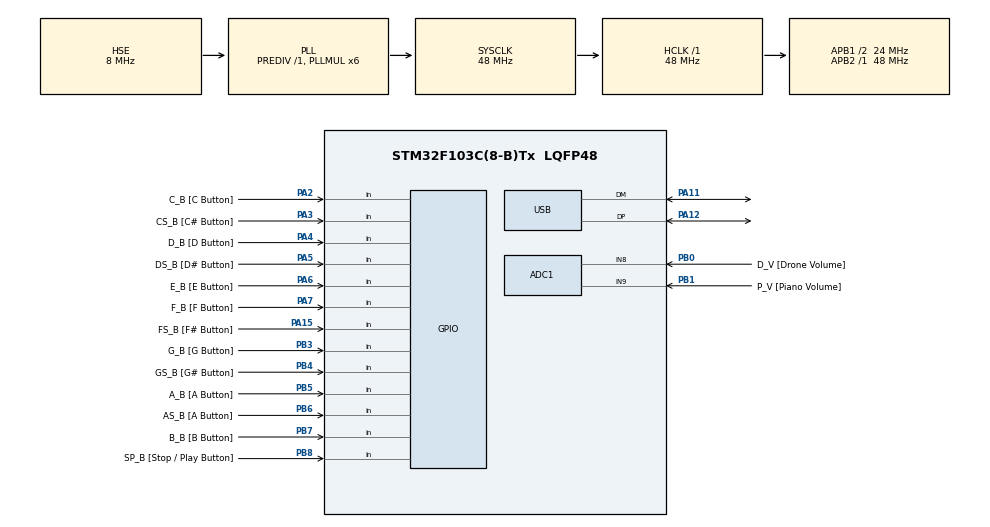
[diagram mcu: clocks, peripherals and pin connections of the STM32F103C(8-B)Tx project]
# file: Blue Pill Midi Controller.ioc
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ADC1.Channel-2\#ChannelRegularConversion=ADC_CHANNEL_8
ADC1.Channel-3\#ChannelRegularConversion=ADC_CHANNEL_9
ADC1.NbrOfConversion=2
ADC1.NbrOfConversionFlag=1
ADC1.Rank-2\#ChannelRegularConversion=1
ADC1.Rank-3\#ChannelRegularConversion=2
ADC1.SamplingTime-2\#ChannelRegularConversion=ADC_SAMPLETIME_1CYCLE_5
ADC1.SamplingTime-3\#ChannelRegularConversion=ADC_SAMPLETIME_1CYCLE_5
ADC1.master=1
Mcu.Family=STM32F1
Mcu.Name=STM32F103C(8-B)Tx
Mcu.Package=LQFP48
NVIC.PriorityGroup=NVIC_PRIORITYGROUP_4
NVIC.TIM2_IRQn=true\:0\:0\:false\:false\:true\:true\:true\:true
NVIC.USB_LP_CAN1_RX0_IRQn=true\:0\:0\:false\:false\:true\:false\:true\:true
PA11.Mode=Device
PA11.Signal=USB_DM
PA12.Mode=Device
PA12.Signal=USB_DP
PA13.Mode=Serial_Wire
PA13.Signal=SYS_JTMS-SWDIO
PA14.Mode=Serial_Wire
PA14.Signal=SYS_JTCK-SWCLK
PA15.GPIO_Label=FS_B [F\# Button]
PA15.GPIO_PuPd=GPIO_PULLUP
PA15.Signal=GPIO_Input
PA2.GPIO_Label=C_B [C Button]
PA2.GPIO_PuPd=GPIO_PULLUP
PA2.Signal=GPIO_Input
PA3.GPIO_Label=CS_B [C\# Button]
PA3.GPIO_PuPd=GPIO_PULLUP
PA3.Signal=GPIO_Input
PA4.GPIO_Label=D_B [D Button]
PA4.GPIO_PuPd=GPIO_PULLUP
PA4.Signal=GPIO_Input
PA5.GPIO_Label=DS_B [D\# Button]
PA5.GPIO_PuPd=GPIO_PULLUP
PA5.Signal=GPIO_Input
PA6.GPIO_Label=E_B [E Button]
PA6.GPIO_PuPd=GPIO_PULLUP
PA6.Signal=GPIO_Input
PA7.GPIO_Label=F_B [F Button]
PA7.GPIO_PuPd=GPIO_PULLUP
PA7.Signal=GPIO_Input
PB0.GPIO_Label=D_V [Drone Volume]
PB0.Signal=ADCx_IN8
PB1.GPIO_Label=P_V [Piano Volume]
PB1.Signal=ADCx_IN9
PB3.GPIO_Label=G_B [G Button]
PB3.GPIO_PuPd=GPIO_PULLUP
PB3.Signal=GPIO_Input
PB4.GPIO_Label=GS_B [G\# Button]
PB4.GPIO_PuPd=GPIO_PULLUP
PB4.Signal=GPIO_Input
PB5.GPIO_Label=A_B [A Button]
PB5.GPIO_PuPd=GPIO_PULLUP
PB5.Signal=GPIO_Input
PB6.GPIO_Label=AS_B [A Button]
PB6.GPIO_PuPd=GPIO_PULLUP
PB6.Signal=GPIO_Input
PB7.GPIO_Label=B_B [B Button]
PB7.GPIO_PuPd=GPIO_PULLUP
PB7.Signal=GPIO_Input
PB8.GPIO_Label=SP_B [Stop / Play Button]
PB8.GPIO_PuPd=GPIO_PULLUP
PB8.Signal=GPIO_Input
PD0-OSC_IN.Mode=HSE-External-Oscillator
PD0-OSC_IN.Signal=RCC_OSC_IN
PD1-OSC_OUT.Mode=HSE-External-Oscillator
PD1-OSC_OUT.Signal=RCC_OSC_OUT
ProjectManager.HeapSize=0x200
ProjectManager.StackSize=0x400
ProjectManager.TargetToolchain=STM32CubeIDE
RCC.ADCPresc=RCC_ADCPCLK2_DIV4
RCC.AHBFreq_Value=48000000
RCC.APB1CLKDivider=RCC_HCLK_DIV2
RCC.APB1Freq_Value=24000000
RCC.APB1TimFreq_Value=48000000
RCC.APB2Freq_Value=48000000
RCC.APB2TimFreq_Value=48000000
RCC.HCLKFreq_Value=48000000
RCC.PLLMUL=RCC_PLL_MUL6
RCC.SYSCLKFreq_VALUE=48000000
RCC.SYSCLKSource=RCC_SYSCLKSOURCE_PLLCLK
RCC.USBFreq_Value=48000000
SH.ADCx_IN8.0=ADC1_IN8,IN8
SH.ADCx_IN9.0=ADC1_IN9,IN9
TIM2.Period=799
TIM2.Prescaler=359
USB_DEVICE.CLASS_NAME_FS=HID
USB_DEVICE.MANUFACTURER_STRING=Vandar Systems
USB_DEVICE.PRODUCT_STRING_HID_FS=Vandar Midi Controller
USB_DEVICE.VirtualMode=Hid
USB_DEVICE.VirtualModeFS=Hid_FS
VP_TIM2_VS_ClockSourceINT.Mode=Internal
VP_USB_DEVICE_VS_USB_DEVICE_HID_FS.Mode=HID_FS
board=custom

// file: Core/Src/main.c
/* USER CODE BEGIN Header */
/**
  ******************************************************************************
  * @file           : main.c
  * @brief          : Main program body
  ******************************************************************************
  * @attention
  *
  * Copyright (c) 2025 STMicroelectronics.
  * All rights reserved.
  *
  * This software is licensed under terms that can be found in the LICENSE file
  * in the root directory of this software component.
  * If no LICENSE file comes with this software, it is provided AS-IS.
  *
  ******************************************************************************
  */
/* USER CODE END Header */
#include "main.h"
#include "usb_device.h"

/* USER CODE BEGIN Includes */
#include "usbd_midi.h"
/* USER CODE END Includes */

ADC_HandleTypeDef hadc1;

TIM_HandleTypeDef htim2;

/* USER CODE BEGIN PV */
extern USBD_HandleTypeDef hUsbDeviceFS;

extern uint16_t D_previous;
extern uint16_t D_current;
extern uint16_t D_ADC_val[2];

extern uint16_t P_previous;
extern uint16_t P_current;
extern uint16_t P_ADC_val[2];

extern float alpha;

extern uint8_t D_vol_message [4];
extern uint8_t P_vol_message [4];
/* USER CODE END PV */

void SystemClock_Config(void);
static void MX_GPIO_Init(void);
static void MX_ADC1_Init(void);
static void MX_TIM2_Init(void);

int main(void)
{

  /* MCU Configuration--------------------------------------------------------*/

  /* Reset of all peripherals, Initializes the Flash interface and the Systick. */
  HAL_Init();

  /* Configure the system clock */
  SystemClock_Config();

  /* Initialize all configured peripherals */
  MX_GPIO_Init();
  MX_USB_DEVICE_Init();
  MX_ADC1_Init();
  MX_TIM2_Init();
  /* USER CODE BEGIN 2 */
//  HAL_ADC_Start (&hadc1);
//  HAL_ADC_PollForConversion (&hadc1, 100);
//  D_ADC_val[0] = HAL_ADC_GetValue (&hadc1);
//
//  HAL_ADC_Start (&hadc1);
//  HAL_ADC_PollForConversion (&hadc1, 100);
//  P_ADC_val[0] = HAL_ADC_GetValue (&hadc1);
//
//  HAL_ADC_Start (&hadc1);
//  HAL_ADC_PollForConversion (&hadc1, 100);
//  D_ADC_val[1] = HAL_ADC_GetValue (&hadc1);
//
//  HAL_ADC_Start (&hadc1);
//  HAL_ADC_PollForConversion (&hadc1, 100);
//  P_ADC_val[1] = HAL_ADC_GetValue (&hadc1);
//
//  D_current = (alpha * D_ADC_val[1]) + ((1 - alpha) * D_ADC_val[0]);
//  D_current = (D_current * 127) / 4095;
//  D_previous = D_current;
//
//  P_current = (alpha * P_ADC_val[1]) + ((1 - alpha) * P_ADC_val[0]);
//  P_current = (P_current * 127) / 4095;
//  P_previous = P_current;
//
//  D_vol_message [3] = D_current;
//  P_vol_message [3] = P_current;
//
//  while (USBD_MIDI_GetState (&hUsbDeviceFS) != MIDI_IDLE) {}
//  USBD_MIDI_SendPackets (&hUsbDeviceFS, D_vol_message, 4);
//
//  while (USBD_MIDI_GetState (&hUsbDeviceFS) != MIDI_IDLE) {}
//  USBD_MIDI_SendPackets (&hUsbDeviceFS, P_vol_message, 4);

  HAL_NVIC_SetPriority (TIM2_IRQn, 0, 0);
  HAL_NVIC_EnableIRQ (TIM2_IRQn);
  HAL_TIM_Base_Start_IT (&htim2);
  /* USER CODE END 2 */

  /* Infinite loop */
  while (1)
  {

  }
}

void SystemClock_Config(void)
{
  RCC_OscInitTypeDef RCC_OscInitStruct = {0};
  RCC_ClkInitTypeDef RCC_ClkInitStruct = {0};
  RCC_PeriphCLKInitTypeDef PeriphClkInit = {0};

  /** Initializes the RCC Oscillators according to the specified parameters
  * in the RCC_OscInitTypeDef structure.
  */
  RCC_OscInitStruct.OscillatorType = RCC_OSCILLATORTYPE_HSE;
  RCC_OscInitStruct.HSEState = RCC_HSE_ON;
  RCC_OscInitStruct.HSEPredivValue = RCC_HSE_PREDIV_DIV1;
  RCC_OscInitStruct.HSIState = RCC_HSI_ON;
  RCC_OscInitStruct.PLL.PLLState = RCC_PLL_ON;
  RCC_OscInitStruct.PLL.PLLSource = RCC_PLLSOURCE_HSE;
  RCC_OscInitStruct.PLL.PLLMUL = RCC_PLL_MUL6;
  if (HAL_RCC_OscConfig(&RCC_OscInitStruct) != HAL_OK)
  {
    Error_Handler();
  }

  /** Initializes the CPU, AHB and APB buses clocks
  */
  RCC_ClkInitStruct.ClockType = RCC_CLOCKTYPE_HCLK|RCC_CLOCKTYPE_SYSCLK
                              |RCC_CLOCKTYPE_PCLK1|RCC_CLOCKTYPE_PCLK2;
  RCC_ClkInitStruct.SYSCLKSource = RCC_SYSCLKSOURCE_PLLCLK;
  RCC_ClkInitStruct.AHBCLKDivider = RCC_SYSCLK_DIV1;
  RCC_ClkInitStruct.APB1CLKDivider = RCC_HCLK_DIV2;
  RCC_ClkInitStruct.APB2CLKDivider = RCC_HCLK_DIV1;

  if (HAL_RCC_ClockConfig(&RCC_ClkInitStruct, FLASH_LATENCY_1) != HAL_OK)
  {
    Error_Handler();
  }
  PeriphClkInit.PeriphClockSelection = RCC_PERIPHCLK_ADC|RCC_PERIPHCLK_USB;
  PeriphClkInit.AdcClockSelection = RCC_ADCPCLK2_DIV4;
  PeriphClkInit.UsbClockSelection = RCC_USBCLKSOURCE_PLL;
  if (HAL_RCCEx_PeriphCLKConfig(&PeriphClkInit) != HAL_OK)
  {
    Error_Handler();
  }
}

static void MX_ADC1_Init(void)
{

  ADC_ChannelConfTypeDef sConfig = {0};

  /** Common config
  */
  hadc1.Instance = ADC1;
  hadc1.Init.ScanConvMode = ADC_SCAN_ENABLE;
  hadc1.Init.ContinuousConvMode = DISABLE;
  hadc1.Init.DiscontinuousConvMode = DISABLE;
  hadc1.Init.ExternalTrigConv = ADC_SOFTWARE_START;
  hadc1.Init.DataAlign = ADC_DATAALIGN_RIGHT;
  hadc1.Init.NbrOfConversion = 2;
  if (HAL_ADC_Init(&hadc1) != HAL_OK)
  {
    Error_Handler();
  }

  /** Configure Regular Channel
  */
  sConfig.Channel = ADC_CHANNEL_8;
  sConfig.Rank = ADC_REGULAR_RANK_1;
  sConfig.SamplingTime = ADC_SAMPLETIME_1CYCLE_5;
  if (HAL_ADC_ConfigChannel(&hadc1, &sConfig) != HAL_OK)
  {
    Error_Handler();
  }

  /** Configure Regular Channel
  */
  sConfig.Channel = ADC_CHANNEL_9;
  sConfig.Rank = ADC_REGULAR_RANK_2;
  if (HAL_ADC_ConfigChannel(&hadc1, &sConfig) != HAL_OK)
  {
    Error_Handler();
  }

}

static void MX_TIM2_Init(void)
{

  TIM_ClockConfigTypeDef sClockSourceConfig = {0};
  TIM_MasterConfigTypeDef sMasterConfig = {0};

  htim2.Instance = TIM2;
  htim2.Init.Prescaler = 359;
  htim2.Init.CounterMode = TIM_COUNTERMODE_UP;
  htim2.Init.Period = 799;
  htim2.Init.ClockDivision = TIM_CLOCKDIVISION_DIV1;
  htim2.Init.AutoReloadPreload = TIM_AUTORELOAD_PRELOAD_DISABLE;
  if (HAL_TIM_Base_Init(&htim2) != HAL_OK)
  {
    Error_Handler();
  }
  sClockSourceConfig.ClockSource = TIM_CLOCKSOURCE_INTERNAL;
  if (HAL_TIM_ConfigClockSource(&htim2, &sClockSourceConfig) != HAL_OK)
  {
    Error_Handler();
  }
  sMasterConfig.MasterOutputTrigger = TIM_TRGO_RESET;
  sMasterConfig.MasterSlaveMode = TIM_MASTERSLAVEMODE_DISABLE;
  if (HAL_TIMEx_MasterConfigSynchronization(&htim2, &sMasterConfig) != HAL_OK)
  {
    Error_Handler();
  }

}

static void MX_GPIO_Init(void)
{
  GPIO_InitTypeDef GPIO_InitStruct = {0};

  /* GPIO Ports Clock Enable */
  __HAL_RCC_GPIOD_CLK_ENABLE();
  __HAL_RCC_GPIOA_CLK_ENABLE();
  __HAL_RCC_GPIOB_CLK_ENABLE();

  /*Configure GPIO pins : C_B_Pin CS_B_Pin D_B_Pin DS_B_Pin
                           E_B_Pin F_B_Pin FS_B_Pin */
  GPIO_InitStruct.Pin = C_B_Pin|CS_B_Pin|D_B_Pin|DS_B_Pin
                          |E_B_Pin|F_B_Pin|FS_B_Pin;
  GPIO_InitStruct.Mode = GPIO_MODE_INPUT;
  GPIO_InitStruct.Pull = GPIO_PULLUP;
  HAL_GPIO_Init(GPIOA, &GPIO_InitStruct);

  /*Configure GPIO pins : G_B_Pin GS_B_Pin A_B_Pin AS_B_Pin
                           B_B_Pin SP_B_Pin */
  GPIO_InitStruct.Pin = G_B_Pin|GS_B_Pin|A_B_Pin|AS_B_Pin
                          |B_B_Pin|SP_B_Pin;
  GPIO_InitStruct.Mode = GPIO_MODE_INPUT;
  GPIO_InitStruct.Pull = GPIO_PULLUP;
  HAL_GPIO_Init(GPIOB, &GPIO_InitStruct);

}

void Error_Handler(void)
{
  __disable_irq();
  while (1)
  {
  }
}
